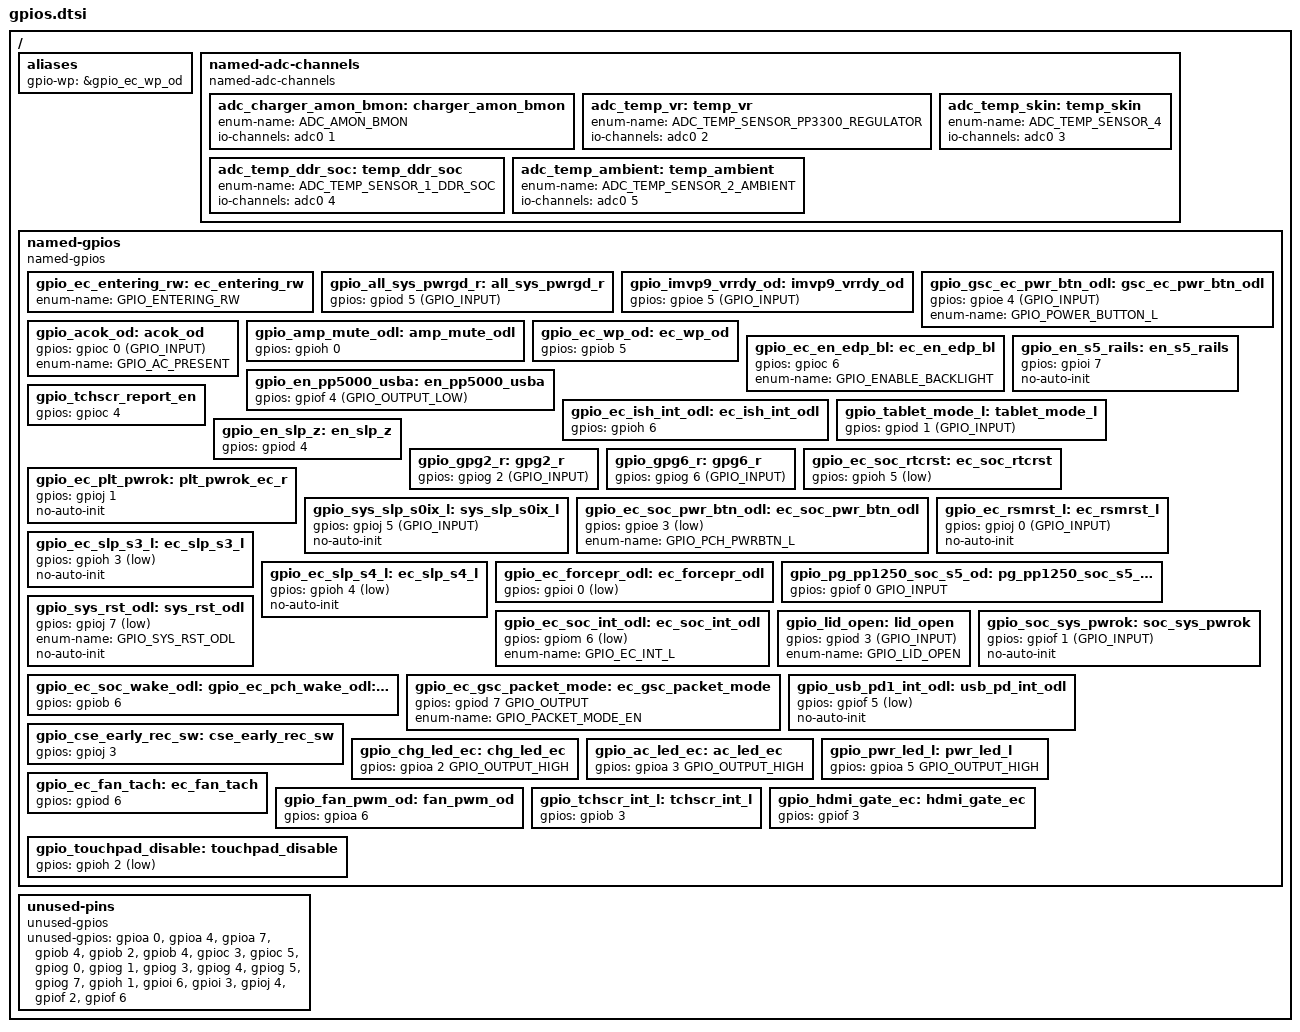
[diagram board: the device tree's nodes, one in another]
/* Copyright 2025 The ChromiumOS Authors
 * Use of this source code is governed by a BSD-style license that can be
 * found in the LICENSE file.
 */

/ {
	aliases {
		gpio-wp = &gpio_ec_wp_od;
	};

	named-adc-channels {
		compatible = "named-adc-channels";

		adc_charger_amon_bmon: charger_amon_bmon {
			enum-name = "ADC_AMON_BMON";
			io-channels = <&adc0 1>;
		};
		adc_temp_vr: temp_vr {
			enum-name = "ADC_TEMP_SENSOR_PP3300_REGULATOR";
			io-channels = <&adc0 2>;
		};
		adc_temp_skin: temp_skin {
			enum-name = "ADC_TEMP_SENSOR_4";
			io-channels = <&adc0 3>;
		};
		adc_temp_ddr_soc: temp_ddr_soc {
			enum-name = "ADC_TEMP_SENSOR_1_DDR_SOC";
			io-channels = <&adc0 4>;
		};
		adc_temp_ambient: temp_ambient {
			enum-name = "ADC_TEMP_SENSOR_2_AMBIENT";
			io-channels = <&adc0 5>;
		};
	};
	
	named-gpios {
		compatible = "named-gpios";

		/* The legacy system code requires GPIO_ENTERING_RW symbol */
		gpio_ec_entering_rw: ec_entering_rw {
			enum-name = "GPIO_ENTERING_RW";
		};
		gpio_all_sys_pwrgd_r: all_sys_pwrgd_r {
			gpios = <&gpiod 5 (GPIO_INPUT)>;
		};
		gpio_imvp9_vrrdy_od: imvp9_vrrdy_od {
			gpios = <&gpioe 5 (GPIO_INPUT)>;
		};
		gpio_gsc_ec_pwr_btn_odl: gsc_ec_pwr_btn_odl {
			gpios = <&gpioe 4 (GPIO_INPUT)>;
			enum-name = "GPIO_POWER_BUTTON_L";
		};
		gpio_acok_od: acok_od {
			gpios = <&gpioc 0 (GPIO_INPUT)>;
			enum-name = "GPIO_AC_PRESENT";
		};
		gpio_amp_mute_odl: amp_mute_odl {
			gpios = <&gpioh 0 (GPIO_OUTPUT_LOW | GPIO_OPEN_DRAIN)>;
		};
		gpio_ec_wp_od: ec_wp_od {
			gpios = <&gpiob 5 (GPIO_INPUT | GPIO_ACTIVE_HIGH)>;
		};
		gpio_ec_en_edp_bl: ec_en_edp_bl {
			gpios = <&gpioc 6 (GPIO_OUTPUT | GPIO_ACTIVE_HIGH | GPIO_OUTPUT_INIT_HIGH)>;
			enum-name = "GPIO_ENABLE_BACKLIGHT";
		};
		gpio_en_pp5000_usba: en_pp5000_usba {
			gpios = <&gpiof 4 (GPIO_OUTPUT_LOW)>;
		};
		/* Power sequencing signal needed by temp sensor driver */
		gpio_en_s5_rails: en_s5_rails {
			gpios = <&gpioi 7 (GPIO_OUTPUT | GPIO_ACTIVE_HIGH | GPIO_OUTPUT_INIT_LOW)>;
			no-auto-init;
		};
		gpio_tchscr_report_en: gpio_tchscr_report_en {
			gpios = <&gpioc 4 (GPIO_INPUT | GPIO_PULL_UP)>;
		};
		gpio_ec_ish_int_odl: ec_ish_int_odl {
			gpios = <&gpioh 6 (GPIO_INPUT | GPIO_VOLTAGE_1P8)>;
		};
		gpio_tablet_mode_l: tablet_mode_l {
			gpios = <&gpiod 1 (GPIO_INPUT)>;
		};
		gpio_en_slp_z: en_slp_z {
			gpios = <&gpiod 4 (GPIO_OUTPUT | GPIO_ACTIVE_HIGH)>;
		};
		gpio_gpg2_r: gpg2_r {
			gpios = <&gpiog 2 (GPIO_INPUT)>;
		};
		gpio_gpg6_r: gpg6_r {
			gpios = <&gpiog 6 (GPIO_INPUT)>;
		};
		gpio_ec_soc_rtcrst: ec_soc_rtcrst {
			gpios = <&gpioh 5 (GPIO_INPUT | GPIO_ACTIVE_LOW)>;
		};
		gpio_ec_plt_pwrok: plt_pwrok_ec_r {
			gpios = <&gpioj 1 (GPIO_OUTPUT | GPIO_ACTIVE_HIGH | GPIO_OUTPUT_INIT_LOW)>;
			no-auto-init;
		};
		gpio_sys_slp_s0ix_l: sys_slp_s0ix_l {
			gpios = <&gpioj 5 (GPIO_INPUT)>;
			no-auto-init;
		};
		gpio_ec_soc_pwr_btn_odl: ec_soc_pwr_btn_odl {
			gpios = <&gpioe 3 (GPIO_OUTPUT | GPIO_OPEN_DRAIN | GPIO_ACTIVE_LOW)>;
			enum-name = "GPIO_PCH_PWRBTN_L";
		};
		gpio_ec_rsmrst_l: ec_rsmrst_l {
			gpios = <&gpioj 0 (GPIO_INPUT)>;
			no-auto-init;
		};
		gpio_ec_slp_s3_l: ec_slp_s3_l {
			gpios = <&gpioh 3 (GPIO_INPUT | GPIO_ACTIVE_LOW)>;
			no-auto-init;
		};
		gpio_ec_slp_s4_l: ec_slp_s4_l {
			gpios = <&gpioh 4 (GPIO_INPUT | GPIO_ACTIVE_LOW)>;
			no-auto-init;
		};
		gpio_ec_forcepr_odl: ec_forcepr_odl {
			gpios = <&gpioi 0 (GPIO_INPUT | GPIO_ACTIVE_LOW)>;
		};
		gpio_pg_pp1250_soc_s5_od: pg_pp1250_soc_s5_od {
			gpios = <&gpiof 0 GPIO_INPUT>;
		};
		gpio_sys_rst_odl: sys_rst_odl {
			gpios = <&gpioj 7 (GPIO_OUTPUT | GPIO_OPEN_DRAIN | GPIO_ACTIVE_LOW | GPIO_OUTPUT_INIT_HIGH)>;
			enum-name = "GPIO_SYS_RST_ODL";
			no-auto-init;
		};
		gpio_ec_soc_int_odl: ec_soc_int_odl {
			gpios = <&gpiom 6 (GPIO_OUTPUT | GPIO_OPEN_DRAIN | GPIO_ACTIVE_LOW)>;
			enum-name = "GPIO_EC_INT_L";
		};
		gpio_lid_open: lid_open {
			gpios = <&gpiod 3 (GPIO_INPUT)>;
			enum-name = "GPIO_LID_OPEN";
		};
		gpio_ec_soc_wake_odl: ec_soc_wake_odl {
			gpios = <&gpiob 6 (GPIO_OUTPUT | GPIO_OPEN_DRAIN | GPIO_ACTIVE_HIGH | GPIO_OUTPUT_INIT_HIGH)>;
		};
		gpio_soc_sys_pwrok: soc_sys_pwrok {
			gpios = <&gpiof 1 (GPIO_INPUT)>;
			no-auto-init;
		};
		gpio_ec_gsc_packet_mode: ec_gsc_packet_mode {
			gpios = <&gpiod 7 GPIO_OUTPUT>;
			enum-name = "GPIO_PACKET_MODE_EN";
		};
		gpio_usb_pd1_int_odl: usb_pd_int_odl {
			gpios = <&gpiof 5 (GPIO_INPUT | GPIO_ACTIVE_LOW)>;
			no-auto-init;
		};
		gpio_cse_early_rec_sw: cse_early_rec_sw {
			gpios = <&gpioj 3 (GPIO_OUTPUT | GPIO_OPEN_DRAIN | GPIO_ACTIVE_HIGH | GPIO_OUTPUT_INIT_LOW)>;
		};
		gpio_chg_led_ec: chg_led_ec {
			gpios = <&gpioa 2 GPIO_OUTPUT_HIGH>;
		};
		gpio_ac_led_ec: ac_led_ec {
			gpios = <&gpioa 3 GPIO_OUTPUT_HIGH>;
		};
		gpio_pwr_led_l: pwr_led_l{
			gpios = <&gpioa 5 GPIO_OUTPUT_HIGH>;
		};
		gpio_ec_fan_tach: ec_fan_tach {
			gpios = <&gpiod 6 (GPIO_INPUT | GPIO_PULL_UP)>;
		};
		gpio_fan_pwm_od: fan_pwm_od {
			gpios = <&gpioa 6 (GPIO_OUTPUT | GPIO_ACTIVE_HIGH)>;
		};
		gpio_tchscr_int_l: tchscr_int_l{
			gpios = <&gpiob 3 (GPIO_INPUT | GPIO_PULL_UP)>;
		};
		gpio_hdmi_gate_ec: hdmi_gate_ec{
			gpios = <&gpiof 3 (GPIO_OUTPUT | GPIO_ACTIVE_HIGH)>;
		};
		gpio_touchpad_disable: touchpad_disable{
			gpios = <&gpioh 2 (GPIO_OUTPUT | GPIO_ACTIVE_LOW)>;
		};
	};

	unused-pins {
		compatible = "unused-gpios";

		unused-gpios =
			<&gpioa 0 0>, /* EC_KB_CAP_LED_L */
			<&gpioa 4 0>, /* FN_LED_L */
			<&gpioa 7 0>, /* ME_FLASH_EN_N */
			<&gpiob 4 0>, /* CAMERA_WP_EC */
			<&gpiob 2 0>, /* PCSPKR */
			<&gpiob 4 0>, /* CAMERA_WP_EC */
			<&gpioc 3 0>, /* CPU_ID */
			<&gpioc 5 0>, /* EC_PROJECT_ID */
			<&gpiog 0 0>, /* SPARE GPG0 */
			<&gpiog 1 0>, /* USB_C1_HV_DISABLE_EC */
			<&gpiog 3 0>, /* SPI_EC_CS_BIOS_L */
			<&gpiog 4 0>, /* SPI_EC_DO_BIOS_DI */
			<&gpiog 5 0>, /* SPI_EC_DI_BIOS_DO */
			<&gpiog 7 0>, /* SPI_EC_CLK */
			<&gpioh 1 0>, /* WOL_PWEN */
			<&gpioi 6 0>, /* EC_TOP_SWAP */
			<&gpioi 3 0>, /* I_ADP_EC */
			<&gpioj 4 0>, /* EC_AC_PRESENT_OD_R */
			<&gpiof 2 0>, /* PHASE_ID */
			<&gpiof 6 0>; /* EC_ACCEL_DB_INT_L */
	};
};

/* The eSPI shim requires this GPIO nodelabel */
gpio_ec_pch_wake_odl: &gpio_ec_soc_wake_odl {};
